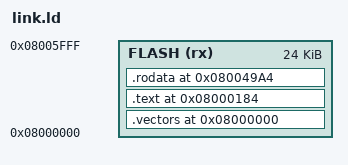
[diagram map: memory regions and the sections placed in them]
/* link.ld - memory layout of the stock FNIRSI 2C53T bootloader, rebuilt from source.
 * Layout: vector table 0x08000000,
 * the original functions in their original order from 0x08000184, the fixed data from 0x080049A4 (strings,
 * byte tables, scatter-load region table, packed RAM image) to 0x08005873.  The settings / calibration page
 * at 0x08006000 is not part of this image and is never linked over (FLASH ends at 0x08006000).
 * RAM addresses are absolute in the code (0x20000000..0x20001A07: initial values unpacked at reset, the
 * rest zeroed; stack top 0x20001A08). */
MEMORY
{
  FLASH (rx) : ORIGIN = 0x08000000, LENGTH = 0x08006000 - 0x08000000
}
ENTRY(reset_handler)
SECTIONS
{
  .vectors 0x08000000 : { KEEP(*(.vectors)) } > FLASH
  .text 0x08000184 :
  {
    KEEP(*(.text.scatter_load_then_start))                         /* 0x08000184 */
    KEEP(*(.text.scatter_load_regions))                            /* 0x0800018c */
    KEEP(*(.text.unpack_literal_run_stream))                       /* 0x080001c0 */
    KEEP(*(.text.zero_fill_region))                                /* 0x0800021c */
    KEEP(*(.text.call_set_fpscr))                                  /* 0x08000238 */
    KEEP(*(.text.return_only))                                     /* 0x08000240 */
    KEEP(*(.text.enter_main))                                      /* 0x08000244 */
    KEEP(*(.text.fn_08000252))                                     /* 0x08000252 */
    KEEP(*(.text.fn_08000256))                                     /* 0x08000256 */
    KEEP(*(.text.reset_handler))                                   /* 0x08000264 */
    KEEP(*(.text.halt_loop_286))                                   /* 0x08000286 */
    KEEP(*(.text.halt_loop_288))                                   /* 0x08000288 */
    KEEP(*(.text.halt_loop_28a))                                   /* 0x0800028a */
    KEEP(*(.text.halt_loop_28c))                                   /* 0x0800028c */
    KEEP(*(.text.halt_loop_28e))                                   /* 0x0800028e */
    KEEP(*(.text.halt_loop_290))                                   /* 0x08000290 */
    KEEP(*(.text.halt_loop_292))                                   /* 0x08000292 */
    KEEP(*(.text.halt_loop_294))                                   /* 0x08000294 */
    KEEP(*(.text.halt_loop_296))                                   /* 0x08000296 */
    KEEP(*(.text.default_irq_handler))                             /* 0x08000298 */
    KEEP(*(.text.heap_stack_constants))                            /* 0x0800029c */
    KEEP(*(.text.return_only_2c0))                                 /* 0x080002c0 */
    KEEP(*(.text.return_only_2c2))                                 /* 0x080002c2 */
    KEEP(*(.text.return_only_2c4))                                 /* 0x080002c4 */
    KEEP(*(.text.return_only_2c6))                                 /* 0x080002c6 */
    KEEP(*(.text.return_only_2c8))                                 /* 0x080002c8 */
    KEEP(*(.text.setup_stack_and_clear_16_words))                  /* 0x080002ca */
    KEEP(*(.text.fn_08000314))                                     /* 0x08000314 */
    KEEP(*(.text.get_address_200015a4))                            /* 0x08000328 */
    KEEP(*(.text.bus_fault_handler))                               /* 0x08000330 */
    KEEP(*(.text.halt_loop_332))                                   /* 0x08000332 */
    KEEP(*(.text.debug_monitor_handler))                           /* 0x08000334 */
    KEEP(*(.text.hard_fault_handler))                              /* 0x08000336 */
    KEEP(*(.text.halt_loop_338))                                   /* 0x08000338 */
    KEEP(*(.text.gpio_init_33c))                                   /* 0x0800033c */
    KEEP(*(.text.gpio_init_3f8))                                   /* 0x080003f8 */
    KEEP(*(.text.gpio_init_4b0))                                   /* 0x080004b0 */
    KEEP(*(.text.gpio_40010c00_pin8_config_write_10))              /* 0x08000564 */
    KEEP(*(.text.fill_window_with_halfword))                       /* 0x080005ac */
    KEEP(*(.text.set_orientation_and_window))                      /* 0x080005dc */
    KEEP(*(.text.write_halfword_at_xy))                            /* 0x080006c4 */
    KEEP(*(.text.send_init_sequence_6001fffe))                     /* 0x080006e0 */
    KEEP(*(.text.write_window_xy_to_dims))                         /* 0x080008a0 */
    KEEP(*(.text.write_halfword_60020000))                         /* 0x080008f8 */
    KEEP(*(.text.write_halfword_6001fffe))                         /* 0x08000904 */
    KEEP(*(.text.write_halfword_60020000_b))                       /* 0x08000910 */
    KEEP(*(.text.write_ram_44c_to_6001fffe))                       /* 0x0800091c */
    KEEP(*(.text.mem_manage_handler))                              /* 0x0800092c */
    KEEP(*(.text.halt_loop_92e))                                   /* 0x0800092e */
    KEEP(*(.text.nmi_handler))                                     /* 0x08000930 */
    KEEP(*(.text.pendsv_handler))                                  /* 0x08000932 */
    KEEP(*(.text.gpio_40011000_pin9_config_write_14))              /* 0x08000934 */
    KEEP(*(.text.svcall_handler))                                  /* 0x0800097c */
    KEEP(*(.text.systick_handler))                                 /* 0x0800097e */
    KEEP(*(.text.init_fpu_clock_vtor))                             /* 0x08000980 */
    KEEP(*(.text.irq20_handler))                                   /* 0x080009f0 */
    KEEP(*(.text.usage_fault_handler))                             /* 0x08000a00 */
    KEEP(*(.text.halt_loop_a02))                                   /* 0x08000a02 */
    KEEP(*(.text.return_only_a04))                                 /* 0x08000a04 */
    KEEP(*(.text.write_40015804_bits))                             /* 0x08000a08 */
    KEEP(*(.text.write_4001580c))                                  /* 0x08000a38 */
    KEEP(*(.text.write_40015810))                                  /* 0x08000a44 */
    KEEP(*(.text.write_40015814))                                  /* 0x08000a50 */
    KEEP(*(.text.validate_usbc_packet_and_dispatch))               /* 0x08000a5c */
    KEEP(*(.text.scsi_op_1e_no_data))                              /* 0x08000b10 */
    KEEP(*(.text.scsi_op_25_read_capacity))                        /* 0x08000b22 */
    KEEP(*(.text.check_lba_range_or_set_sense))                    /* 0x08000bb8 */
    KEEP(*(.text.fn_08000bf0))                                     /* 0x08000bf0 */
    KEEP(*(.text.scsi_dispatch_by_opcode))                         /* 0x08000c2c */
    KEEP(*(.text.fn_08000d2e))                                     /* 0x08000d2e */
    KEEP(*(.text.fn_08000d30))                                     /* 0x08000d30 */
    KEEP(*(.text.fn_08000d32))                                     /* 0x08000d32 */
    KEEP(*(.text.fn_08000d42))                                     /* 0x08000d42 */
    KEEP(*(.text.fn_08000d50))                                     /* 0x08000d50 */
    KEEP(*(.text.fn_08000d58))                                     /* 0x08000d58 */
    KEEP(*(.text.fn_08000d9c))                                     /* 0x08000d9c */
    KEEP(*(.text.scsi_op_23_build_response))                       /* 0x08000dd4 */
    KEEP(*(.text.start_command_packet_receive))                    /* 0x08000e70 */
    KEEP(*(.text.scsi_op_12_copy_response))                        /* 0x08000eb4 */
    KEEP(*(.text.scsi_mode_sense_10))                              /* 0x08000f14 */
    KEEP(*(.text.scsi_mode_sense_6))                               /* 0x08000f44 */
    KEEP(*(.text.scsi_read_10))                                    /* 0x08000f74 */
    KEEP(*(.text.scsi_request_sense))                              /* 0x08001088 */
    KEEP(*(.text.fn_080010c8))                                     /* 0x080010c8 */
    KEEP(*(.text.fn_080010f0))                                     /* 0x080010f0 */
    KEEP(*(.text.fn_08001134))                                     /* 0x08001134 */
    KEEP(*(.text.scsi_set_sense))                                  /* 0x08001184 */
    KEEP(*(.text.fn_08001190))                                     /* 0x08001190 */
    KEEP(*(.text.scsi_start_stop_unit))                            /* 0x080011d4 */
    KEEP(*(.text.scsi_test_unit_ready))                            /* 0x080011e6 */
    KEEP(*(.text.scsi_verify_10))                                  /* 0x08001216 */
    KEEP(*(.text.scsi_write_10))                                   /* 0x08001286 */
    KEEP(*(.text.fn_080013cc))                                     /* 0x080013cc */
    KEEP(*(.text.fn_080013e8))                                     /* 0x080013e8 */
    KEEP(*(.text.fn_08001402))                                     /* 0x08001402 */
    KEEP(*(.text.fn_08001408))                                     /* 0x08001408 */
    KEEP(*(.text.fn_08001426))                                     /* 0x08001426 */
    KEEP(*(.text.fn_0800143a))                                     /* 0x0800143a */
    KEEP(*(.text.fn_08001464))                                     /* 0x08001464 */
    KEEP(*(.text.fn_08001478))                                     /* 0x08001478 */
    KEEP(*(.text.fn_0800154a))                                     /* 0x0800154a */
    KEEP(*(.text.set_40023008_bit0))                               /* 0x08001550 */
    KEEP(*(.text.write_40023000_read_back))                        /* 0x08001564 */
    KEEP(*(.text.set_40021004_bits7_4))                            /* 0x08001574 */
    KEEP(*(.text.set_40021004_bits10_8))                           /* 0x08001588 */
    KEEP(*(.text.set_40021004_bits13_11))                          /* 0x0800159c */
    KEEP(*(.text.fn_080015b0))                                     /* 0x080015b0 */
    KEEP(*(.text.fn_080015d8))                                     /* 0x080015d8 */
    KEEP(*(.text.read_bit_40021000_offset))                        /* 0x08001638 */
    KEEP(*(.text.set_40021054_bits13_12))                          /* 0x08001668 */
    KEEP(*(.text.fn_0800167c))                                     /* 0x0800167c */
    KEEP(*(.text.set_40021030_bit25))                              /* 0x080016ac */
    KEEP(*(.text.fn_080016c0))                                     /* 0x080016c0 */
    KEEP(*(.text.set_or_clear_bit_40021000_offset))                /* 0x080016dc */
    KEEP(*(.text.set_or_clear_bit_40021000_offset_b))              /* 0x08001720 */
    KEEP(*(.text.fn_08001764))                                     /* 0x08001764 */
    KEEP(*(.text.fn_080017d0))                                     /* 0x080017d0 */
    KEEP(*(.text.set_40021004_bits1_0))                            /* 0x08001828 */
    KEEP(*(.text.get_40021004_bits3_2))                            /* 0x0800183c */
    KEEP(*(.text.fn_0800184c))                                     /* 0x0800184c */
    KEEP(*(.text.fn_0800186c))                                     /* 0x0800186c */
    KEEP(*(.text.fn_0800188c))                                     /* 0x0800188c */
    KEEP(*(.text.systick_delay))                                   /* 0x080018c4 */
    KEEP(*(.text.fn_08001938))                                     /* 0x08001938 */
    KEEP(*(.text.compare_bytes))                                   /* 0x08001960 */
    KEEP(*(.text.copy_bytes))                                      /* 0x08001980 */
    KEEP(*(.text.fill_bytes))                                      /* 0x08001994 */
    KEEP(*(.text.read_flash_status_bank1))                         /* 0x080019a8 */
    KEEP(*(.text.wait_flash_status_bank1))                         /* 0x080019dc */
    KEEP(*(.text.read_flash_status_bank2))                         /* 0x08001a00 */
    KEEP(*(.text.wait_flash_status_bank2))                         /* 0x08001a34 */
    KEEP(*(.text.fn_08001a58))                                     /* 0x08001a58 */
    KEEP(*(.text.fn_08001ad4))                                     /* 0x08001ad4 */
    KEEP(*(.text.read_bit1_4002201c))                              /* 0x08001b64 */
    KEEP(*(.text.fn_08001b74))                                     /* 0x08001b74 */
    KEEP(*(.text.fn_08001c0c))                                     /* 0x08001c0c */
    KEEP(*(.text.fn_08001cb8))                                     /* 0x08001cb8 */
    KEEP(*(.text.fn_08001cd8))                                     /* 0x08001cd8 */
    KEEP(*(.text.fn_08001d2c))                                     /* 0x08001d2c */
    KEEP(*(.text.fn_08001e24))                                     /* 0x08001e24 */
    KEEP(*(.text.fn_08001ed8))                                     /* 0x08001ed8 */
    KEEP(*(.text.fn_08001f50))                                     /* 0x08001f50 */
    KEEP(*(.text.fn_0800200c))                                     /* 0x0800200c */
    KEEP(*(.text.fn_08002018))                                     /* 0x08002018 */
    KEEP(*(.text.fn_0800202c))                                     /* 0x0800202c */
    KEEP(*(.text.fn_08002058))                                     /* 0x08002058 */
    KEEP(*(.text.fn_0800208c))                                     /* 0x0800208c */
    KEEP(*(.text.fn_080020b0))                                     /* 0x080020b0 */
    KEEP(*(.text.fn_080020f8))                                     /* 0x080020f8 */
    KEEP(*(.text.fn_08002118))                                     /* 0x08002118 */
    KEEP(*(.text.flash_wait_op_a))                                 /* 0x0800214c */
    KEEP(*(.text.flash_erase_sector))                              /* 0x08002170 */
    KEEP(*(.text.flash_status_code_c))                             /* 0x0800224c */
    KEEP(*(.text.flash_wait_op_c))                                 /* 0x08002280 */
    KEEP(*(.text.flash_unlock_keys))                               /* 0x080022a4 */
    KEEP(*(.text.flash_option_erase_then_write_a5))                /* 0x080022c4 */
    KEEP(*(.text.flash_option_program_halfword))                   /* 0x0800235c */
    KEEP(*(.text.flash_program_word))                              /* 0x080023c4 */
    KEEP(*(.text.fn_08002478))                                     /* 0x08002478 */
    KEEP(*(.text.usb_string_config))                               /* 0x08002518 */
    KEEP(*(.text.usb_config_descriptor_ref))                       /* 0x0800254c */
    KEEP(*(.text.usb_device_descriptor_ref))                       /* 0x08002554 */
    KEEP(*(.text.usb_string_interface))                            /* 0x0800255c */
    KEEP(*(.text.usb_langid_descriptor_ref))                       /* 0x08002594 */
    KEEP(*(.text.usb_string_manufacturer))                         /* 0x0800259c */
    KEEP(*(.text.return_zero_080025c4))                            /* 0x080025c4 */
    KEEP(*(.text.usb_string_product))                              /* 0x080025c8 */
    KEEP(*(.text.return_zero_080025fc))                            /* 0x080025fc */
    KEEP(*(.text.usb_serial_descriptor_ref))                       /* 0x08002600 */
    KEEP(*(.text.fn_08002610))                                     /* 0x08002610 */
    KEEP(*(.text.usb_serial_fill))                                 /* 0x0800262c */
    KEEP(*(.text.write_reg_0x14))                                  /* 0x08002660 */
    KEEP(*(.text.write_reg_0x10))                                  /* 0x08002664 */
    KEEP(*(.text.config_record_init_default))                      /* 0x08002668 */
    KEEP(*(.text.config_record_apply_nibbles))                     /* 0x0800267e */
    KEEP(*(.text.reg8_all_bits_set))                               /* 0x08002726 */
    KEEP(*(.text.fn_08002738))                                     /* 0x08002738 */
    KEEP(*(.text.fn_08002784))                                     /* 0x08002784 */
    KEEP(*(.text.draw_glyph))                                      /* 0x080027cc */
    KEEP(*(.text.draw_string))                                     /* 0x080028cc */
    KEEP(*(.text.fn_08002938))                                     /* 0x08002938 */
    KEEP(*(.text.fn_08002a60))                                     /* 0x08002a60 */
    KEEP(*(.text.fn_08002a88))                                     /* 0x08002a88 */
    KEEP(*(.text.fn_08002ab2))                                     /* 0x08002ab2 */
    KEEP(*(.text.nvic_set_priority_enable))                        /* 0x08002adc */
    KEEP(*(.text.scb_set_priority_grouping))                       /* 0x08002ba4 */
    KEEP(*(.text.system_reset))                                    /* 0x08002bcc */
    KEEP(*(.text.fn_08002bf8))                                     /* 0x08002bf8 */
    KEEP(*(.text.fn_08002c68))                                     /* 0x08002c68 */
    KEEP(*(.text.systick_clock_source))                            /* 0x08002d60 */
    KEEP(*(.text.halfword_200000c0_reset))                         /* 0x08002d88 */
    KEEP(*(.text.halfword_200000c0_fetch_add))                     /* 0x08002d94 */
    KEEP(*(.text.fn_08002da8))                                     /* 0x08002da8 */
    KEEP(*(.text.fn_08002e68))                                     /* 0x08002e68 */
    KEEP(*(.text.fn_08002e7a))                                     /* 0x08002e7a */
    KEEP(*(.text.fn_08002e9e))                                     /* 0x08002e9e */
    KEEP(*(.text.fn_08002eb4))                                     /* 0x08002eb4 */
    KEEP(*(.text.fn_08002ecc))                                     /* 0x08002ecc */
    KEEP(*(.text.fn_08003108))                                     /* 0x08003108 */
    KEEP(*(.text.fn_08003620))                                     /* 0x08003620 */
    KEEP(*(.text.fn_08003632))                                     /* 0x08003632 */
    KEEP(*(.text.fn_08003638))                                     /* 0x08003638 */
    KEEP(*(.text.copy_from_200000bc_area))                         /* 0x0800364c */
    KEEP(*(.text.fn_08003678))                                     /* 0x08003678 */
    KEEP(*(.text.fn_0800369c))                                     /* 0x0800369c */
    KEEP(*(.text.copy_to_200000bc_area))                           /* 0x080036b0 */
    KEEP(*(.text.fn_080036dc))                                     /* 0x080036dc */
    KEEP(*(.text.fn_08003730))                                     /* 0x08003730 */
    KEEP(*(.text.fn_080037c0))                                     /* 0x080037c0 */
    KEEP(*(.text.fn_080037cc))                                     /* 0x080037cc */
    KEEP(*(.text.fn_08003886))                                     /* 0x08003886 */
    KEEP(*(.text.fn_080038b2))                                     /* 0x080038b2 */
    KEEP(*(.text.fn_0800392a))                                     /* 0x0800392a */
    KEEP(*(.text.fn_0800397e))                                     /* 0x0800397e */
    KEEP(*(.text.fn_08003996))                                     /* 0x08003996 */
    KEEP(*(.text.fn_080039be))                                     /* 0x080039be */
    KEEP(*(.text.fn_080039d6))                                     /* 0x080039d6 */
    KEEP(*(.text.fn_080039ec))                                     /* 0x080039ec */
    KEEP(*(.text.fn_08003a6c))                                     /* 0x08003a6c */
    KEEP(*(.text.fn_08003a78))                                     /* 0x08003a78 */
    KEEP(*(.text.fn_08003bc4))                                     /* 0x08003bc4 */
    KEEP(*(.text.fn_08003bd0))                                     /* 0x08003bd0 */
    KEEP(*(.text.fn_08003c14))                                     /* 0x08003c14 */
    KEEP(*(.text.init_endpoint_entries))                           /* 0x08003c44 */
    KEEP(*(.text.fn_08003d08))                                     /* 0x08003d08 */
    KEEP(*(.text.fn_08003d2e))                                     /* 0x08003d2e */
    KEEP(*(.text.fn_08003d88))                                     /* 0x08003d88 */
    KEEP(*(.text.fn_08003dfc))                                     /* 0x08003dfc */
    KEEP(*(.text.fn_08003f1c))                                     /* 0x08003f1c */
    KEEP(*(.text.fn_080040f8))                                     /* 0x080040f8 */
    KEEP(*(.text.fn_0800414e))                                     /* 0x0800414e */
    KEEP(*(.text.out_endpoint_length_done))                        /* 0x08004240 */
    KEEP(*(.text.fn_08004254))                                     /* 0x08004254 */
    KEEP(*(.text.hex_digit_pairs))                                 /* 0x08004298 */
    KEEP(*(.text.fn_080042d6))                                     /* 0x080042d6 */
    KEEP(*(.text.fn_0800430e))                                     /* 0x0800430e */
    KEEP(*(.text.fn_080043aa))                                     /* 0x080043aa */
    KEEP(*(.text.fn_080043f0))                                     /* 0x080043f0 */
    KEEP(*(.text.fn_08004444))                                     /* 0x08004444 */
    KEEP(*(.text.fn_0800450c))                                     /* 0x0800450c */
    KEEP(*(.text.fn_08004538))                                     /* 0x08004538 */
    KEEP(*(.text.copy_8_bytes))                                    /* 0x080045c0 */
    KEEP(*(.text.fn_080045e8))                                     /* 0x080045e8 */
    KEEP(*(.text.fn_080045fc))                                     /* 0x080045fc */
    KEEP(*(.text.ascii_to_length_prefixed_halfword_string))        /* 0x08004626 */
    KEEP(*(.text.fn_08004662))                                     /* 0x08004662 */
    KEEP(*(.text.set_byte0_clear_byte1_a0000220))                  /* 0x08004688 */
    KEEP(*(.text.fn_080046b0))                                     /* 0x080046b0 */
    KEEP(*(.text.set_bit0_a0000000))                               /* 0x0800484c */
    KEEP(*(.text.fn_08004862))                                     /* 0x08004862 */
    KEEP(*(.text.fn_080048bc))                                     /* 0x080048bc */
    KEEP(*(.text.init_record_08004862))                            /* 0x08004938 */
    KEEP(*(.text.init_records_080048bc))                           /* 0x08004962 */
    KEEP(*(.text.set_fpscr_3000000))                               /* 0x0800499a */
  } > FLASH
  ASSERT(. == 0x080049a4, "code does not end at 0x080049a4")
  .rodata 0x080049a4 : { KEEP(*(.rodata.fixed)) } > FLASH
  ASSERT(. == 0x08005874, "fixed data does not end at 0x08005874")
  /DISCARD/ : { *(.ARM.attributes) *(.comment) *(.ARM.exidx*) }
}
